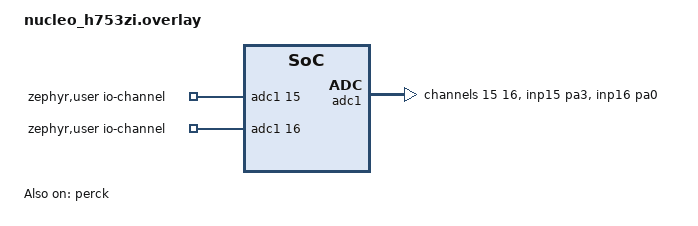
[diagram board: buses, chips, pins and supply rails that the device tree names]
/*
 * Copyright (c) 2026 STMicroelectronics
 *
 * SPDX-License-Identifier: Apache-2.0
 */

/ {
	aliases {
		adc0 = &adc1;
	};

	zephyr,user {
		/* adjust channel number according to pinmux in board.dts */
		io-channels = <&adc1 15>, <&adc1 16>;
	};
};

&perck {
	clocks = <&rcc STM32_SRC_HSE CKPER_SEL(2)>;
	status = "okay";
};

&adc1 {
	clocks = <&rcc STM32_CLOCK(AHB1, 5)>,
		 <&rcc STM32_SRC_CKPER ADC_SEL(2)>;
	clock-names = "adcx", "adc_ker";
	st,adc-clock-source = "ASYNC";
	st,adc-prescaler = <256>;
	pinctrl-0 = <&adc1_inp15_pa3 &adc1_inp16_pa0>;
	#address-cells = <1>;
	#size-cells = <0>;

	channel@f {
		reg = <15>;
		zephyr,gain = "ADC_GAIN_1";
		zephyr,reference = "ADC_REF_INTERNAL";
		zephyr,acquisition-time = <ADC_ACQ_TIME_MAX>;
		zephyr,resolution = <16>;
	};

	channel@10 {
		reg = <16>;
		zephyr,gain = "ADC_GAIN_1";
		zephyr,reference = "ADC_REF_INTERNAL";
		zephyr,acquisition-time = <ADC_ACQ_TIME_MAX>;
		zephyr,resolution = <16>;
	};
};
